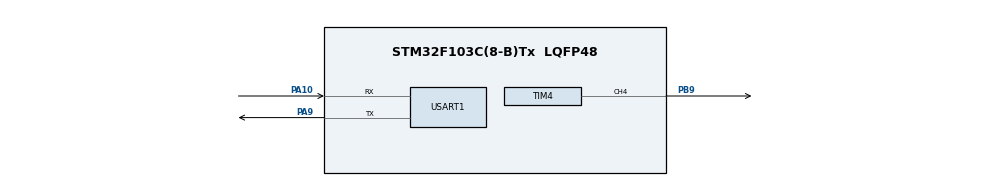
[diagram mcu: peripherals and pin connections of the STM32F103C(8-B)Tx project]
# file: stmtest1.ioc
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Mcu.Family=STM32F1
Mcu.Name=STM32F103C(8-B)Tx
Mcu.Package=LQFP48
NVIC.PriorityGroup=NVIC_PRIORITYGROUP_4
PA10.Mode=Asynchronous
PA10.Signal=USART1_RX
PA9.Mode=Asynchronous
PA9.Signal=USART1_TX
PB9.Signal=S_TIM4_CH4
ProjectManager.HeapSize=0x200
ProjectManager.StackSize=0x400
ProjectManager.TargetToolchain=CMake
RCC.APB1Freq_Value=8000000
RCC.APB2Freq_Value=8000000
SH.S_TIM4_CH4.0=TIM4_CH4,PWM Generation4 CH4
TIM4.Channel-PWM\ Generation4\ CH4=TIM_CHANNEL_4
TIM4.Pulse-PWM\ Generation4\ CH4=0
USART1.VirtualMode=VM_ASYNC
VP_SYS_VS_ND.Mode=No_Debug
VP_TIM4_VS_ClockSourceINT.Mode=Internal
board=custom

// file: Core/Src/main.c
/* USER CODE BEGIN Header */
/**
  ******************************************************************************
  * @file           : main.c
  * @brief          : Main program body
  ******************************************************************************
  * @attention
  *
  * Copyright (c) 2025 STMicroelectronics.
  * All rights reserved.
  *
  * This software is licensed under terms that can be found in the LICENSE file
  * in the root directory of this software component.
  * If no LICENSE file comes with this software, it is provided AS-IS.
  *
  ******************************************************************************
  */
/* USER CODE END Header */
#include "main.h"

#include <string.h>

TIM_HandleTypeDef htim4;

UART_HandleTypeDef huart1;

void SystemClock_Config(void);
static void MX_GPIO_Init(void);
static void MX_USART1_UART_Init(void);
static void MX_TIM4_Init(void);

/* USER CODE BEGIN 0 */
// 改变PWM频率和占空比
static void Buzzer_SetFreq(uint32_t, uint32_t);
/* USER CODE END 0 */

int main(void)
{

  /* MCU Configuration--------------------------------------------------------*/

  /* Reset of all peripherals, Initializes the Flash interface and the Systick. */
  HAL_Init();

  /* Configure the system clock */
  SystemClock_Config();

  /* Initialize all configured peripherals */
  MX_GPIO_Init();
  MX_USART1_UART_Init();
  MX_TIM4_Init();
  /* USER CODE BEGIN 2 */
  HAL_TIM_PWM_Start(&htim4, TIM_CHANNEL_4);
  /* USER CODE END 2 */

  /* Infinite loop */
  /* USER CODE BEGIN WHILE */
  while (1)
  {
    HAL_GPIO_WritePin(GPIOA, GPIO_PIN_0, GPIO_PIN_SET);
    HAL_GPIO_WritePin(GPIOA, GPIO_PIN_1, GPIO_PIN_SET);
    const char * msg = "The red light turned on while the blue one turned off.\n";
    HAL_UART_Transmit(&huart1, (uint8_t *)msg, strlen(msg), HAL_MAX_DELAY);
    Buzzer_SetFreq(1500, 50); // 1500Hz, 50%占空比
    HAL_Delay(1000);

    HAL_GPIO_WritePin(GPIOA, GPIO_PIN_0, GPIO_PIN_RESET);
    HAL_GPIO_WritePin(GPIOA, GPIO_PIN_1, GPIO_PIN_RESET);
    msg = "The blue light turned on while the red one turned off.\n";
    HAL_UART_Transmit(&huart1, (uint8_t *)msg, strlen(msg), HAL_MAX_DELAY);
    Buzzer_SetFreq(2500, 50); // 2500Hz, 50%占空比
    HAL_Delay(1000);
    /* USER CODE END WHILE */

  }
}

void SystemClock_Config(void)
{
  RCC_OscInitTypeDef RCC_OscInitStruct = {0};
  RCC_ClkInitTypeDef RCC_ClkInitStruct = {0};

  /** Initializes the RCC Oscillators according to the specified parameters
  * in the RCC_OscInitTypeDef structure.
  */
  RCC_OscInitStruct.OscillatorType = RCC_OSCILLATORTYPE_HSI;
  RCC_OscInitStruct.HSIState = RCC_HSI_ON;
  RCC_OscInitStruct.HSICalibrationValue = RCC_HSICALIBRATION_DEFAULT;
  RCC_OscInitStruct.PLL.PLLState = RCC_PLL_NONE;
  if (HAL_RCC_OscConfig(&RCC_OscInitStruct) != HAL_OK)
  {
    Error_Handler();
  }

  /** Initializes the CPU, AHB and APB buses clocks
  */
  RCC_ClkInitStruct.ClockType = RCC_CLOCKTYPE_HCLK|RCC_CLOCKTYPE_SYSCLK
                              |RCC_CLOCKTYPE_PCLK1|RCC_CLOCKTYPE_PCLK2;
  RCC_ClkInitStruct.SYSCLKSource = RCC_SYSCLKSOURCE_HSI;
  RCC_ClkInitStruct.AHBCLKDivider = RCC_SYSCLK_DIV1;
  RCC_ClkInitStruct.APB1CLKDivider = RCC_HCLK_DIV1;
  RCC_ClkInitStruct.APB2CLKDivider = RCC_HCLK_DIV1;

  if (HAL_RCC_ClockConfig(&RCC_ClkInitStruct, FLASH_LATENCY_0) != HAL_OK)
  {
    Error_Handler();
  }
}

static void MX_TIM4_Init(void)
{

  TIM_ClockConfigTypeDef sClockSourceConfig = {0};
  TIM_MasterConfigTypeDef sMasterConfig = {0};
  TIM_OC_InitTypeDef sConfigOC = {0};

  htim4.Instance = TIM4;
  htim4.Init.Prescaler = 71;
  htim4.Init.CounterMode = TIM_COUNTERMODE_UP;
  htim4.Init.Period = 999;
  htim4.Init.ClockDivision = TIM_CLOCKDIVISION_DIV1;
  htim4.Init.AutoReloadPreload = TIM_AUTORELOAD_PRELOAD_DISABLE;
  if (HAL_TIM_Base_Init(&htim4) != HAL_OK)
  {
    Error_Handler();
  }
  sClockSourceConfig.ClockSource = TIM_CLOCKSOURCE_INTERNAL;
  if (HAL_TIM_ConfigClockSource(&htim4, &sClockSourceConfig) != HAL_OK)
  {
    Error_Handler();
  }
  if (HAL_TIM_PWM_Init(&htim4) != HAL_OK)
  {
    Error_Handler();
  }
  sMasterConfig.MasterOutputTrigger = TIM_TRGO_RESET;
  sMasterConfig.MasterSlaveMode = TIM_MASTERSLAVEMODE_DISABLE;
  if (HAL_TIMEx_MasterConfigSynchronization(&htim4, &sMasterConfig) != HAL_OK)
  {
    Error_Handler();
  }
  sConfigOC.OCMode = TIM_OCMODE_PWM1;
  sConfigOC.Pulse = 500;
  sConfigOC.OCPolarity = TIM_OCPOLARITY_HIGH;
  sConfigOC.OCFastMode = TIM_OCFAST_DISABLE;
  if (HAL_TIM_PWM_ConfigChannel(&htim4, &sConfigOC, TIM_CHANNEL_4) != HAL_OK)
  {
    Error_Handler();
  }
  HAL_TIM_MspPostInit(&htim4);

}

static void MX_USART1_UART_Init(void)
{

  huart1.Instance = USART1;
  huart1.Init.BaudRate = 115200;
  huart1.Init.WordLength = UART_WORDLENGTH_8B;
  huart1.Init.StopBits = UART_STOPBITS_1;
  huart1.Init.Parity = UART_PARITY_NONE;
  huart1.Init.Mode = UART_MODE_TX_RX;
  huart1.Init.HwFlowCtl = UART_HWCONTROL_NONE;
  huart1.Init.OverSampling = UART_OVERSAMPLING_16;
  if (HAL_UART_Init(&huart1) != HAL_OK)
  {
    Error_Handler();
  }

}

static void MX_GPIO_Init(void)
{

  /* GPIO Ports Clock Enable */
  __HAL_RCC_GPIOA_CLK_ENABLE();
  __HAL_RCC_GPIOB_CLK_ENABLE();

  /* USER CODE BEGIN MX_GPIO_Init_2 */
  GPIO_InitTypeDef GPIO_PA0_InitStruct = {0};
  GPIO_PA0_InitStruct.Pin = GPIO_PIN_0;
  GPIO_PA0_InitStruct.Mode = GPIO_MODE_OUTPUT_PP;
  GPIO_PA0_InitStruct.Pull = GPIO_NOPULL;
  GPIO_PA0_InitStruct.Speed = GPIO_SPEED_FREQ_LOW;
  HAL_GPIO_Init(GPIOA, &GPIO_PA0_InitStruct);

  GPIO_InitTypeDef GPIO_PA1_InitStruct = {0};
  GPIO_PA1_InitStruct.Pin = GPIO_PIN_1;
  GPIO_PA1_InitStruct.Mode = GPIO_MODE_OUTPUT_PP;
  GPIO_PA1_InitStruct.Pull = GPIO_NOPULL;
  GPIO_PA1_InitStruct.Speed = GPIO_SPEED_FREQ_LOW;
  HAL_GPIO_Init(GPIOA, &GPIO_PA1_InitStruct);

  GPIO_InitTypeDef GPIO_PB9_InitStruct = {0};
  GPIO_PB9_InitStruct.Pin = GPIO_PIN_9;
  GPIO_PB9_InitStruct.Mode = GPIO_MODE_AF_PP;
  GPIO_PB9_InitStruct.Speed = GPIO_SPEED_FREQ_LOW;
  HAL_GPIO_Init(GPIOB, &GPIO_PB9_InitStruct);
  /* USER CODE END MX_GPIO_Init_2 */
}

/* USER CODE BEGIN 4 */
// 改变PWM频率和占空比
void Buzzer_SetFreq(uint32_t freq, uint32_t duty_percent)
{
  uint32_t timer_clock = 72000000; // APB1定时器时钟 = 72MHz
  uint32_t prescaler = 72 - 1;     // 先固定预分频为72 (1MHz定时器时钟)
  uint32_t period = (1000000 / freq) - 1; // freq = 频率

  // 修改定时器配置
  htim4.Instance->PSC = prescaler;
  htim4.Instance->ARR = period;

  // 占空比 = duty_percent%
  htim4.Instance->CCR4 = (period + 1) * duty_percent / 100;
}
/* USER CODE END 4 */

void Error_Handler(void)
{
  __disable_irq();
  while (1)
  {
  }
}
